# TIMER1 register map
Registers from a debugger description file.
Registers are 32-bit, read-only, no defined reset value unless marked. A register's access mark holds for its fields unless they carry their own. Addresses are absolute; registers are grouped by the start of their names; lines under a group give offsets from that group; [hi:lo] are bit positions; {n}, {i} and the like mark numbered series; 'fields as' and 'values as' point back to an identical list; <NAME> marks a mode.

## Timer1
{0x51001000+0x20*i} Timer1/LoadCount_{i} access not given (i=0..5)
  [15:0] LoadCount
{0x51001004+0x20*i} Timer1/CurrentCount_{i} (i=0..5)
  [15:0] CurrentCount
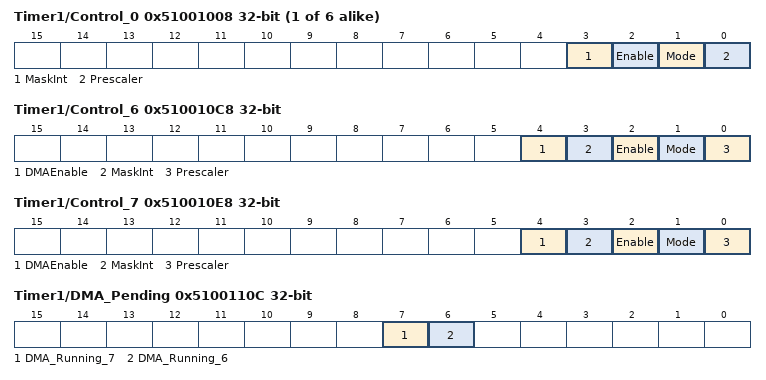
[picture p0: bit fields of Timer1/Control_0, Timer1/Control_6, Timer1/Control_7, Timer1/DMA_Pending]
{0x51001008+0x20*i} Timer1/Control_{i} access not given (i=0..5)
  [3] MaskInt, [2] Enable, [1] Mode, [0] Prescaler
{0x5100100C+0x20*i} Timer1/ClearInt_{i} (i=0..7)
  [0] ClearInt
{0x51001010+0x20*i} Timer1/StatusInt0_{i} (i=0..7)
  [0] StatusInt0
{0x51001014+0x20*i} Timer1/StatusInt1_{i} (i=0..7)
  [0] StatusInt1
0x510010C0 Timer1/LoadCount_6 access not given
  [31:0] LoadCount
0x510010C4 Timer1/CurrentCount_6
  [31:0] CurrentCount
0x510010C8 Timer1/Control_6 access not given
  [4] DMAEnable, [3] MaskInt, [2] Enable, [1] Mode, [0] Prescaler
0x510010E0 Timer1/LoadCount_7 access not given
  [31:0] LoadCount
0x510010E4 Timer1/CurrentCount_7
  [31:0] CurrentCount
0x510010E8 Timer1/Control_7 access not given
  [4] DMAEnable, [3] MaskInt, [2] Enable, [1] Mode, [0] Prescaler
0x51001100 Timer1/AllClearInt
  [7:0] AllClearInt
0x51001104 Timer1/AllStatusInt0
  [7:0] AllStatusInt0
0x51001108 Timer1/AllStatusInt1
  [7:0] AllStatusInt1
0x5100110C Timer1/DMA_Pending
  [7] DMA_Running_7, [6] DMA_Running_6
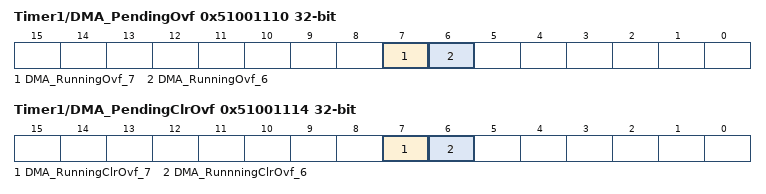
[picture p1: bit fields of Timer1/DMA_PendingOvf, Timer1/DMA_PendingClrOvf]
0x51001110 Timer1/DMA_PendingOvf
  [7] DMA_RunningOvf_7, [6] DMA_RunningOvf_6
0x51001114 Timer1/DMA_PendingClrOvf access not given
  [7] DMA_RunningClrOvf_7, [6] DMA_RunnningClrOvf_6
